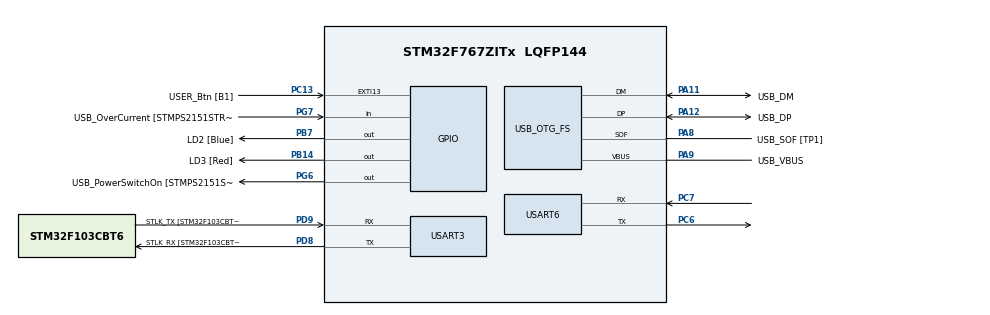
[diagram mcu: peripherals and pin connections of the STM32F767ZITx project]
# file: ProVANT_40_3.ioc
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Dma.Request0=USART6_RX
Dma.USART6_RX.0.Direction=DMA_PERIPH_TO_MEMORY
Dma.USART6_RX.0.FIFOMode=DMA_FIFOMODE_ENABLE
Dma.USART6_RX.0.FIFOThreshold=DMA_FIFO_THRESHOLD_FULL
Dma.USART6_RX.0.Instance=DMA2_Stream1
Dma.USART6_RX.0.MemBurst=DMA_MBURST_SINGLE
Dma.USART6_RX.0.MemDataAlignment=DMA_MDATAALIGN_BYTE
Dma.USART6_RX.0.MemInc=DMA_MINC_ENABLE
Dma.USART6_RX.0.Mode=DMA_NORMAL
Dma.USART6_RX.0.PeriphBurst=DMA_PBURST_SINGLE
Dma.USART6_RX.0.PeriphDataAlignment=DMA_PDATAALIGN_BYTE
Dma.USART6_RX.0.PeriphInc=DMA_PINC_DISABLE
Dma.USART6_RX.0.Priority=DMA_PRIORITY_VERY_HIGH
FREERTOS.Tasks01=defaultTask,0,128,StartDefaultTask,Default,NULL,Dynamic,NULL,NULL;ControllerTask,0,128,Controller,Default,NULL,Dynamic,NULL,NULL;OutputTask,-3,128,Output,Default,NULL,Dynamic,NULL,NULL
Mcu.Family=STM32F7
Mcu.Name=STM32F767ZITx
Mcu.Package=LQFP144
NVIC.DMA2_Stream1_IRQn=true\:5\:0\:false\:false\:true\:true\:false\:true
NVIC.PriorityGroup=NVIC_PRIORITYGROUP_4
NVIC.TIM1_UP_TIM10_IRQn=true\:0\:0\:false\:false\:true\:false\:false\:true
NVIC.TimeBase=TIM1_UP_TIM10_IRQn
NVIC.TimeBaseIP=TIM1
NVIC.USART6_IRQn=true\:5\:0\:true\:false\:true\:false\:true\:true
PA1.GPIO_Label=RMII_REF_CLK [LAN8742A-CZ-TR_REFCLK0]
PA1.Signal=ETH_REF_CLK
PA10.GPIO_Label=USB_ID
PA10.Signal=USB_OTG_FS_ID
PA11.GPIO_Label=USB_DM
PA11.Mode=Device_Only
PA11.Signal=USB_OTG_FS_DM
PA12.GPIO_Label=USB_DP
PA12.Mode=Device_Only
PA12.Signal=USB_OTG_FS_DP
PA13.GPIO_Label=TMS
PA13.Mode=Serial_Wire
PA13.Signal=SYS_JTMS-SWDIO
PA14.GPIO_Label=TCK
PA14.Mode=Serial_Wire
PA14.Signal=SYS_JTCK-SWCLK
PA2.GPIO_Label=RMII_MDIO [LAN8742A-CZ-TR_MDIO]
PA2.Signal=ETH_MDIO
PA7.GPIO_Label=RMII_CRS_DV [LAN8742A-CZ-TR_CRS_DV]
PA7.Signal=ETH_CRS_DV
PA8.GPIO_Label=USB_SOF [TP1]
PA8.Mode=Activate_SOF_FS
PA8.Signal=USB_OTG_FS_SOF
PA9.GPIO_Label=USB_VBUS
PA9.Mode=Activate_VBUS
PA9.Signal=USB_OTG_FS_VBUS
PB13.GPIO_Label=RMII_TXD1 [LAN8742A-CZ-TR_TXD1]
PB13.Signal=ETH_TXD1
PB14.GPIO_Label=LD3 [Red]
PB14.Signal=GPIO_Output
PB3.GPIO_Label=SWO
PB3.Signal=SYS_JTDO-SWO
PB7.GPIO_Label=LD2 [Blue]
PB7.Signal=GPIO_Output
PC1.GPIO_Label=RMII_MDC [LAN8742A-CZ-TR_MDC]
PC1.Signal=ETH_MDC
PC13.GPIO_Label=USER_Btn [B1]
PC13.Signal=GPXTI13
PC14/OSC32_IN.Mode=LSE-External-Oscillator
PC14/OSC32_IN.Signal=RCC_OSC32_IN
PC15/OSC32_OUT.Mode=LSE-External-Oscillator
PC15/OSC32_OUT.Signal=RCC_OSC32_OUT
PC4.GPIO_Label=RMII_RXD0 [LAN8742A-CZ-TR_RXD0]
PC4.Signal=ETH_RXD0
PC5.GPIO_Label=RMII_RXD1 [LAN8742A-CZ-TR_RXD1]
PC5.Signal=ETH_RXD1
PC6.Mode=Asynchronous
PC6.Signal=USART6_TX
PC7.Mode=Asynchronous
PC7.Signal=USART6_RX
PD8.GPIO_Label=STLK_RX [STM32F103CBT6_PA3]
PD8.Mode=Asynchronous
PD8.Signal=USART3_TX
PD9.GPIO_Label=STLK_TX [STM32F103CBT6_PA2]
PD9.Mode=Asynchronous
PD9.Signal=USART3_RX
PG11.GPIO_Label=RMII_TX_EN [LAN8742A-CZ-TR_TXEN]
PG11.Signal=ETH_TX_EN
PG13.GPIO_Label=RMII_TXD0 [LAN8742A-CZ-TR_TXD0]
PG13.Signal=ETH_TXD0
PG6.GPIO_Label=USB_PowerSwitchOn [STMPS2151STR_EN]
PG6.Signal=GPIO_Output
PG7.GPIO_Label=USB_OverCurrent [STMPS2151STR_FAULT]
PG7.Signal=GPIO_Input
PH0/OSC_IN.GPIO_Label=MCO [STM32F103CBT6_PA8]
PH0/OSC_IN.Mode=HSE-External-Clock-Source
PH0/OSC_IN.Signal=RCC_OSC_IN
PH1/OSC_OUT.Mode=HSE-External-Clock-Source
PH1/OSC_OUT.Signal=RCC_OSC_OUT
ProjectManager.HeapSize=0x200
ProjectManager.StackSize=0x400
ProjectManager.TargetToolchain=SW4STM32
RCC.48MHZClocksFreq_Value=24000000
RCC.AHBFreq_Value=216000000
RCC.APB1CLKDivider=RCC_HCLK_DIV4
RCC.APB1Freq_Value=54000000
RCC.APB1TimFreq_Value=108000000
RCC.APB2CLKDivider=RCC_HCLK_DIV2
RCC.APB2Freq_Value=108000000
RCC.APB2TimFreq_Value=216000000
RCC.CortexFreq_Value=216000000
RCC.HCLKFreq_Value=216000000
RCC.HSE_VALUE=8000000
RCC.HSI_VALUE=16000000
RCC.PLLM=4
RCC.PLLMUL=RCC_PLL_MUL9
RCC.PLLN=216
RCC.PLLQ=9
RCC.PRESCALERUSB=RCC_USBCLKSOURCE_PLL_DIV1_5
RCC.SYSCLKFreq_VALUE=216000000
RCC.SYSCLKSource=RCC_SYSCLKSOURCE_PLLCLK
RCC.SYSCLKSourceVirtual=RCC_SYSCLKSOURCE_PLLCLK
RCC.USBFreq_Value=48000000
RCC.VCOOutputFreq_Value=432000000
USART3.VirtualMode-Asynchronous=VM_ASYNC
USART6.VirtualMode-Asynchronous=VM_ASYNC
USB_OTG_FS.VirtualMode=Device_Only
VP_FREERTOS_VS_CMSIS_V1.Mode=CMSIS_V1
VP_SYS_VS_tim1.Mode=TIM1
board=NUCLEO-F767ZI

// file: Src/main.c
#include "main.h"
#include "cmsis_os.h"
#include "code.h"

int main(void)
{
  /* USER CODE BEGIN 1 */
	initialise_monitor_handles();
	printf("Começou programa!\n");
    DWT->CTRL |= (1 << 0); // Enable CYCCNT in DWN_CTRL
  /* USER CODE END 1 */

  /* MCU Configuration--------------------------------------------------------*/

  /* Reset of all peripherals, Initializes the Flash interface and the Systick. */
  HAL_Init();

  /* Configure the system clock */
  SystemClock_Config();

  /* Initialize all configured peripherals */
  MX_GPIO_Init();
  MX_DMA_Init();
  MX_USART6_UART_Init();
  MX_USB_OTG_FS_PCD_Init();
  MX_USART3_UART_Init();
  MX_SPI1_Init(void);
  MX_SPI5_Init(void);

  /* Create the thread(s) */
  /* definition and creation of defaultTask */
  osThreadDef(defaultTask, StartDefaultTask, osPriorityIdle, 0, 128);
  defaultTaskHandle = osThreadCreate(osThread(defaultTask), NULL);

  /* definition and creation of ControllerTask */
  osThreadDef(ControllerTask, Controller, osPriorityNormal, 0, 512);
  ControllerTaskHandle = osThreadCreate(osThread(ControllerTask), NULL);

  /* definition and creation of OutputTask */
  osThreadDef(OutputTask, Output, osPriorityHigh, 0, 128);
  OutputTaskHandle = osThreadCreate(osThread(OutputTask), NULL);

  /* Start scheduler */
  osKernelStart();

  /* We should never get here as control is now taken by the scheduler */

  /* Infinite loop */
  /* USER CODE BEGIN WHILE */
  //c_io_protocolP2P_init(&huart6);
  while (1)
  {
    /* USER CODE END WHILE */

  }
}

/************************ (C) COPYRIGHT STMicroelectronics *****END OF FILE****/
